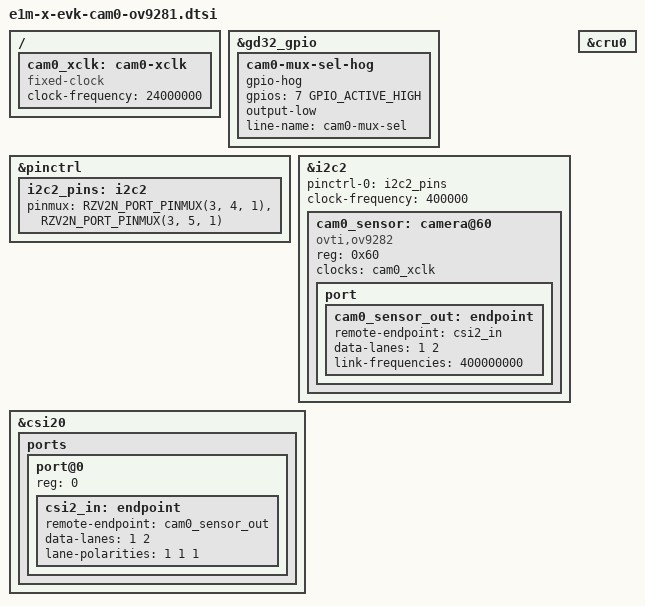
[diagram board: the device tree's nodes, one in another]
// SPDX-License-Identifier: (GPL-2.0-only OR BSD-2-Clause)
/*
 * OPT-IN camera path: one OmniVision OV9281 (monochrome, RPi-style 15-pin
 * module, 2-lane MIPI CSI-2) on the E1M-X-EVK CAM0 connector (J5) ->
 * RZ/V2N MIPI CSI-2 receiver 0 -> CRU0 -> /dev/video*.
 *
 * NOT part of the default dtb.  Pulled in only by the wrapper dts
 * (e1m-v2n101-x-evk-cam0.dts / e1m-v2m101-x-evk-cam0.dts) when
 * ALP_ENABLE_CAM0_OV9281 = "1".  Mutually exclusive with
 * e1m-x-evk-cam0-imx219.dtsi (same labels, same nodes; the bbappend
 * refuses both).
 *
 * STATUS: bench-proven on E1M-V2M103 + X-EVK J5 (needs patches 0016, 0017).
 * The csi20 / cru0 graph and the caveats in
 * e1m-x-evk-cam0-imx219.dtsi (labels from the Renesas BSP convention, CAM0
 * = receiver 0, no sensor power sequencing from Linux) apply unchanged.
 *
 * Carrier wiring this fragment relies on:
 *   - CSI lanes: J5 carries 2 data lanes + clock, routed through a 2:1 CSI
 *     mux (TI TS3DV642-Q1) onto E1M-X CSI0 lanes 0/1 + clock.  Mux SEL1 is
 *     strapped high on the carrier; SEL2 = E1M IO16 (CAM0_MUX.SEL).  Per
 *     the mux datasheet (Table 8-1, SEL1 = H) SEL2 = L enables the A
 *     channels (J5), SEL2 = H the B channels (the other CAM0 connector).
 *     On the V2N/V2M SoM IO16 is a GD32 bridge GPIO, line 7 of
 *     &gd32_gpio (see its gpio-line-names in e1m-v2n-som.dtsi), hogged LOW
 *     below.  The bridge driver replays outputs after a late bridge start
 *     (#2308), so a hog is safe.
 *   - Camera I2C: J5 SDA/SCL go through a level shifter to E1M-X I2C2
 *     (pads E63/E64) = RZ/V2N RIIC2 (P34 SDA / P35 SCL) = &i2c2.
 *   - Camera enable: J5 pin 11 (CAM_GPIO) is pulled low by an N-FET whose
 *     gate is CAM0_EN = E1M IO18.  The carrier pulls that gate down, so by
 *     default the FET is off and pin 11 is left to the module.  On V2M
 *     IO18 is a DEEPX DX-M1 GPIO/strap, not a Linux GPIO, so it is
 *     deliberately NOT modelled.
 *   - Power: the J5 3V3 rail is always on.
 *   - Clock: RPi-style modules carry their own 24 MHz oscillator; the
 *     driver still wants an xvclk handle, so a fixed-clock stands in.
 *
 * Sensor / driver facts (6.1.141-cip43, drivers/media/i2c/ov9282.c):
 *   - Matches only "ovti,ov9282"; the OV9281 shares chip ID 0x9281, so it
 *     probes with this compatible.
 *   - 2 data lanes, link frequency 400000000 Hz only (the endpoint is
 *     rejected otherwise), one mode: 1280x720 MEDIA_BUS_FMT_Y10_1X10.  The
 *     sensor's native 1280x800 mode is NOT in the 6.1 driver.
 *   - Optional reset-gpios; none is wired here.
 *   - I2C address 0x60 (typical RPi OV9281 modules); some modules strap
 *     0x70 -- change `reg` and the unit name if i2cdetect shows that.
 *   - Y10_1X10 -> CR10 via patch 0016.  See docs/v2n-camera-csi.md.
 */

/ {
	cam0_xclk: cam0-xclk {
		compatible = "fixed-clock";
		#clock-cells = <0>;
		clock-frequency = <24000000>;
	};
};

&gd32_gpio {
	/* CAM0_MUX.SEL (E1M IO16) = line 7: LOW selects the J5 (A) channels. */
	cam0-mux-sel-hog {
		gpio-hog;
		gpios = <7 GPIO_ACTIVE_HIGH>;
		output-low;
		line-name = "cam0-mux-sel";
	};
};

&pinctrl {
	/* E1M-X I2C2 = RIIC2: SDA P34, SCL P35
	 * (metadata/e1m_modules/v2n/renesas-peripheral-map.tsv). */
	i2c2_pins: i2c2 {
		pinmux = <RZV2N_PORT_PINMUX(3, 4, 1)>, /* I2C2_SDA */
			 <RZV2N_PORT_PINMUX(3, 5, 1)>; /* I2C2_SCL */
	};
};

&i2c2 {
	pinctrl-0 = <&i2c2_pins>;
	pinctrl-names = "default";
	clock-frequency = <400000>;
	status = "okay";

	cam0_sensor: camera@60 {
		compatible = "ovti,ov9282";
		reg = <0x60>;
		clocks = <&cam0_xclk>;

		port {
			cam0_sensor_out: endpoint {
				remote-endpoint = <&csi2_in>;
				data-lanes = <1 2>;
				link-frequencies = /bits/ 64 <400000000>;
			};
		};
	};
};

&csi20 {
	status = "okay";

	ports {
		#address-cells = <1>;
		#size-cells = <0>;

		port@0 {
			reg = <0>;
			csi2_in: endpoint {
				remote-endpoint = <&cam0_sensor_out>;
				data-lanes = <1 2>;
				/*
				 * Clock + 2 data lanes inverted: bench-proven on E1M-V2M103 +
				 * X-EVK J5 that the CSI0 P/N pairs arrive swapped at the
				 * RZ/V2N receiver (rzg2l-csi2 patch 0017 writes CRUm_SWAPCTL).
				 * Where in the chain the swap happens (camera FPC, carrier or
				 * SoM symbol) is TBD; the netlists name P/N consistently.  Set
				 * on the receiver side because that is what the driver parses.
				 */
				lane-polarities = <1 1 1>;
			};
		};
	};
};

&cru0 {
	status = "okay";
};
